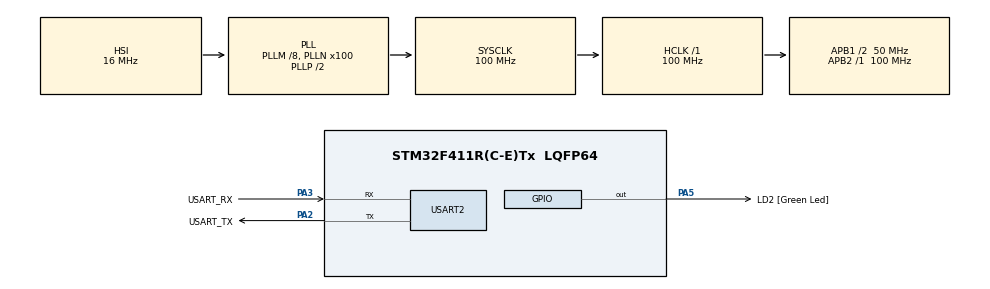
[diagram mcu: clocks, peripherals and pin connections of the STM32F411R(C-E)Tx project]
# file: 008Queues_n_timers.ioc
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Mcu.Family=STM32F4
Mcu.Name=STM32F411R(C-E)Tx
Mcu.Package=LQFP64
NVIC.PriorityGroup=NVIC_PRIORITYGROUP_4
NVIC.TIM3_IRQn=true\:15\:0\:false\:false\:true\:false\:true\:true
NVIC.TimeBase=TIM3_IRQn
NVIC.TimeBaseIP=TIM3
NVIC.USART2_IRQn=true\:6\:0\:true\:false\:true\:true\:true\:true
PA13.GPIO_Label=TMS
PA13.Signal=SYS_JTMS-SWDIO
PA14.GPIO_Label=TCK
PA14.Signal=SYS_JTCK-SWCLK
PA2.GPIO_Label=USART_TX
PA2.Mode=Asynchronous
PA2.Signal=USART2_TX
PA3.GPIO_Label=USART_RX
PA3.Mode=Asynchronous
PA3.Signal=USART2_RX
PA5.GPIO_Label=LD2 [Green Led]
PA5.Signal=GPIO_Output
PB3.GPIO_Label=SWO
PB3.Signal=SYS_JTDO-SWO
PC14-OSC32_IN.Signal=RCC_OSC32_IN
PC15-OSC32_OUT.Signal=RCC_OSC32_OUT
PH0\ -\ OSC_IN.Signal=RCC_OSC_IN
PH1\ -\ OSC_OUT.Signal=RCC_OSC_OUT
ProjectManager.HeapSize=0x200
ProjectManager.StackSize=0x400
ProjectManager.TargetToolchain=STM32CubeIDE
RCC.48MHZClocksFreq_Value=50000000
RCC.AHBFreq_Value=100000000
RCC.APB1CLKDivider=RCC_HCLK_DIV2
RCC.APB1Freq_Value=50000000
RCC.APB1TimFreq_Value=100000000
RCC.APB2Freq_Value=100000000
RCC.APB2TimFreq_Value=100000000
RCC.CortexFreq_Value=100000000
RCC.FLatency-AdvancedSettings=FLASH_LATENCY_3
RCC.HCLKFreq_Value=100000000
RCC.HSE_VALUE=8000000
RCC.HSI_VALUE=16000000
RCC.LSE_VALUE=32768
RCC.PLLM=8
RCC.PLLN=100
RCC.SYSCLKFreq_VALUE=100000000
RCC.SYSCLKSource=RCC_SYSCLKSOURCE_PLLCLK
RCC.VCOOutputFreq_Value=200000000
RTC.HourFormat=RTC_HOURFORMAT_12
USART2.VirtualMode=VM_ASYNC
VP_RTC_VS_RTC_Activate.Mode=RTC_Enabled
VP_SYS_VS_tim3.Mode=TIM3
board=NUCLEO-F411RE

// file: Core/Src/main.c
/* USER CODE BEGIN Header */
/**
 ******************************************************************************
 * @file           : main.c
 * @brief          : Main program body
 ******************************************************************************
 * @attention
 *
 * Copyright (c) 2024 STMicroelectronics.
 * All rights reserved.
 *
 * This software is licensed under terms that can be found in the LICENSE file
 * in the root directory of this software component.
 * If no LICENSE file comes with this software, it is provided AS-IS.
 *
 ******************************************************************************
 */
/* USER CODE END Header */
#include "main.h"

RTC_HandleTypeDef hrtc;

UART_HandleTypeDef huart2;

QueueHandle_t cmd_queue, print_queue;

TaskHandle_t menu_task_handle;
TaskHandle_t led_task_handle;
TaskHandle_t rtc_task_handle;
TaskHandle_t cmd_task_handle;
TaskHandle_t print_task_handle;

TimerHandle_t rtc_timer;

uint8_t user_data;

state_t curr_state = sMainMenu;

TimerHandle_t handle_led_timer[4];

void led_effect_callback(TimerHandle_t xTimer);

/* USER CODE BEGIN PV */

#define DWT_CTRL (*(volatile uint32_t *)0xE0001000)

/* USER CODE END PV */

void SystemClock_Config(void);
static void MX_GPIO_Init(void);
static void MX_RTC_Init(void);
static void MX_USART2_UART_Init(void);

int main(void) {
	/* USER CODE BEGIN 1 */

	BaseType_t status;

	/* USER CODE END 1 */

	/* MCU Configuration--------------------------------------------------------*/

	/* Reset of all peripherals, Initializes the Flash interface and the Systick. */
	HAL_Init();

	/* Configure the system clock */
	SystemClock_Config();

	/* Initialize all configured peripherals */
	MX_GPIO_Init();
	MX_RTC_Init();
	MX_USART2_UART_Init();
	/* USER CODE BEGIN 2 */

	//SEGGER_SYSVIEW_Start();
	status = xTaskCreate(menu_task, "menu_task", 250,
	NULL, 3, &menu_task_handle);

	configASSERT(status == pdPASS);

	status = xTaskCreate(led_task, "led_task", 250,
	NULL, 2, &led_task_handle);

	configASSERT(status == pdPASS);

	status = xTaskCreate(rtc_task, "rtc_task", 250,
	NULL, 2, &rtc_task_handle);

	configASSERT(status == pdPASS);

	status = xTaskCreate(cmd_task, "cmd_task", 250,
	NULL, 2, &cmd_task_handle);

	configASSERT(status == pdPASS);

	status = xTaskCreate(print_task, "print_task", 250,
	NULL, 2, &print_task_handle);

	configASSERT(status == pdPASS);

	cmd_queue = xQueueCreate(10, sizeof(char));

	configASSERT(cmd_queue != NULL);

	print_queue = xQueueCreate(10, sizeof(size_t));

	configASSERT(print_queue != NULL);

	HAL_UART_Receive_IT(&huart2, &user_data, 1);

	//create sofware timers
	for (int i = 0; i < 4; i++) {
		handle_led_timer[i] = xTimerCreate("led_timer",
				pdMS_TO_TICKS(250 * (i + 1)),
				pdTRUE, (void*) (i + 1), led_effect_callback);
	}

	//start the freeRTOS scheduler
	vTaskStartScheduler();

	/* USER CODE END 2 */

	/* Infinite loop */
	while (1) {

	}
}

void SystemClock_Config(void) {
	RCC_OscInitTypeDef RCC_OscInitStruct = { 0 };
	RCC_ClkInitTypeDef RCC_ClkInitStruct = { 0 };

	/** Configure the main internal regulator output voltage
	 */
	__HAL_RCC_PWR_CLK_ENABLE();
	__HAL_PWR_VOLTAGESCALING_CONFIG(PWR_REGULATOR_VOLTAGE_SCALE1);

	/** Initializes the RCC Oscillators according to the specified parameters
	 * in the RCC_OscInitTypeDef structure.
	 */
	RCC_OscInitStruct.OscillatorType = RCC_OSCILLATORTYPE_HSI
			| RCC_OSCILLATORTYPE_LSI;
	RCC_OscInitStruct.HSIState = RCC_HSI_ON;
	RCC_OscInitStruct.HSICalibrationValue = RCC_HSICALIBRATION_DEFAULT;
	RCC_OscInitStruct.LSIState = RCC_LSI_ON;
	RCC_OscInitStruct.PLL.PLLState = RCC_PLL_ON;
	RCC_OscInitStruct.PLL.PLLSource = RCC_PLLSOURCE_HSI;
	RCC_OscInitStruct.PLL.PLLM = 8;
	RCC_OscInitStruct.PLL.PLLN = 100;
	RCC_OscInitStruct.PLL.PLLP = RCC_PLLP_DIV2;
	RCC_OscInitStruct.PLL.PLLQ = 4;
	if (HAL_RCC_OscConfig(&RCC_OscInitStruct) != HAL_OK) {
		Error_Handler();
	}

	/** Initializes the CPU, AHB and APB buses clocks
	 */
	RCC_ClkInitStruct.ClockType = RCC_CLOCKTYPE_HCLK | RCC_CLOCKTYPE_SYSCLK
			| RCC_CLOCKTYPE_PCLK1 | RCC_CLOCKTYPE_PCLK2;
	RCC_ClkInitStruct.SYSCLKSource = RCC_SYSCLKSOURCE_PLLCLK;
	RCC_ClkInitStruct.AHBCLKDivider = RCC_SYSCLK_DIV1;
	RCC_ClkInitStruct.APB1CLKDivider = RCC_HCLK_DIV2;
	RCC_ClkInitStruct.APB2CLKDivider = RCC_HCLK_DIV1;

	if (HAL_RCC_ClockConfig(&RCC_ClkInitStruct, FLASH_LATENCY_3) != HAL_OK) {
		Error_Handler();
	}
}

static void MX_RTC_Init(void) {

	/** Initialize RTC Only
	 */
	hrtc.Instance = RTC;
	hrtc.Init.HourFormat = RTC_HOURFORMAT_12;
	hrtc.Init.AsynchPrediv = 127;
	hrtc.Init.SynchPrediv = 255;
	hrtc.Init.OutPut = RTC_OUTPUT_DISABLE;
	hrtc.Init.OutPutPolarity = RTC_OUTPUT_POLARITY_HIGH;
	hrtc.Init.OutPutType = RTC_OUTPUT_TYPE_OPENDRAIN;
	if (HAL_RTC_Init(&hrtc) != HAL_OK) {
		Error_Handler();
	}

}

static void MX_USART2_UART_Init(void) {

	huart2.Instance = USART2;
	huart2.Init.BaudRate = 115200;
	huart2.Init.WordLength = UART_WORDLENGTH_8B;
	huart2.Init.StopBits = UART_STOPBITS_1;
	huart2.Init.Parity = UART_PARITY_NONE;
	huart2.Init.Mode = UART_MODE_TX_RX;
	huart2.Init.HwFlowCtl = UART_HWCONTROL_NONE;
	huart2.Init.OverSampling = UART_OVERSAMPLING_16;
	if (HAL_UART_Init(&huart2) != HAL_OK) {
		Error_Handler();
	}

}

static void MX_GPIO_Init(void) {
	GPIO_InitTypeDef GPIO_InitStruct = { 0 };

	/* GPIO Ports Clock Enable */
	__HAL_RCC_GPIOC_CLK_ENABLE();
	__HAL_RCC_GPIOH_CLK_ENABLE();
	__HAL_RCC_GPIOA_CLK_ENABLE();
	__HAL_RCC_GPIOB_CLK_ENABLE();

	/*Configure GPIO pin Output Level */
	HAL_GPIO_WritePin(LD2_GPIO_Port, LD2_Pin, GPIO_PIN_RESET);

	/*Configure GPIO pin : LD2_Pin */
	GPIO_InitStruct.Pin = LD2_Pin;
	GPIO_InitStruct.Mode = GPIO_MODE_OUTPUT_PP;
	GPIO_InitStruct.Pull = GPIO_NOPULL;
	GPIO_InitStruct.Speed = GPIO_SPEED_FREQ_LOW;
	HAL_GPIO_Init(LD2_GPIO_Port, &GPIO_InitStruct);

}

/* USER CODE BEGIN 4 */
void led_effect_callback(TimerHandle_t xTimer) {
	int id;
	id = (uint32_t) pvTimerGetTimerID(xTimer);

	switch (id) {
	case 1:
		LED_effect1();
		break;
	case 2:
		LED_effect2();
		break;
	case 3:
		LED_effect3();
		break;
	case 4:
		LED_effect4();
		break;
	}
}

void HAL_UART_RxCpltCallback(UART_HandleTypeDef *huart) {

	uint8_t dummy;

	if (!xQueueIsQueueFullFromISR(cmd_queue)) {
		/*Enqueue data byte */
		xQueueSendFromISR(cmd_queue, (void* )&user_data, NULL);
	} else {
		if (user_data == 3) {
			/*Make sure that last data byte of the queue is '\n' */
			xQueueReceiveFromISR(cmd_queue, (void*) &dummy, NULL);
			xQueueSendFromISR(cmd_queue, (void* )&user_data, NULL);
		}
	}

	/*Send notification to command handling task if user_data = '\n' */
	if (user_data == 3) {
		/*send notification to command handling task */
		xTaskNotifyFromISR(cmd_task_handle, 0, eNoAction, NULL);
	}

	/* Enable UART data byte reception again in IT mode */
	HAL_UART_Receive_IT(&huart2, (uint8_t*) &user_data, 1);

}

/* USER CODE END 4 */

void HAL_TIM_PeriodElapsedCallback(TIM_HandleTypeDef *htim) {
	if (htim->Instance == TIM3) {
		HAL_IncTick();
	}
}

void Error_Handler(void) {
	__disable_irq();
	while (1) {
	}
}
